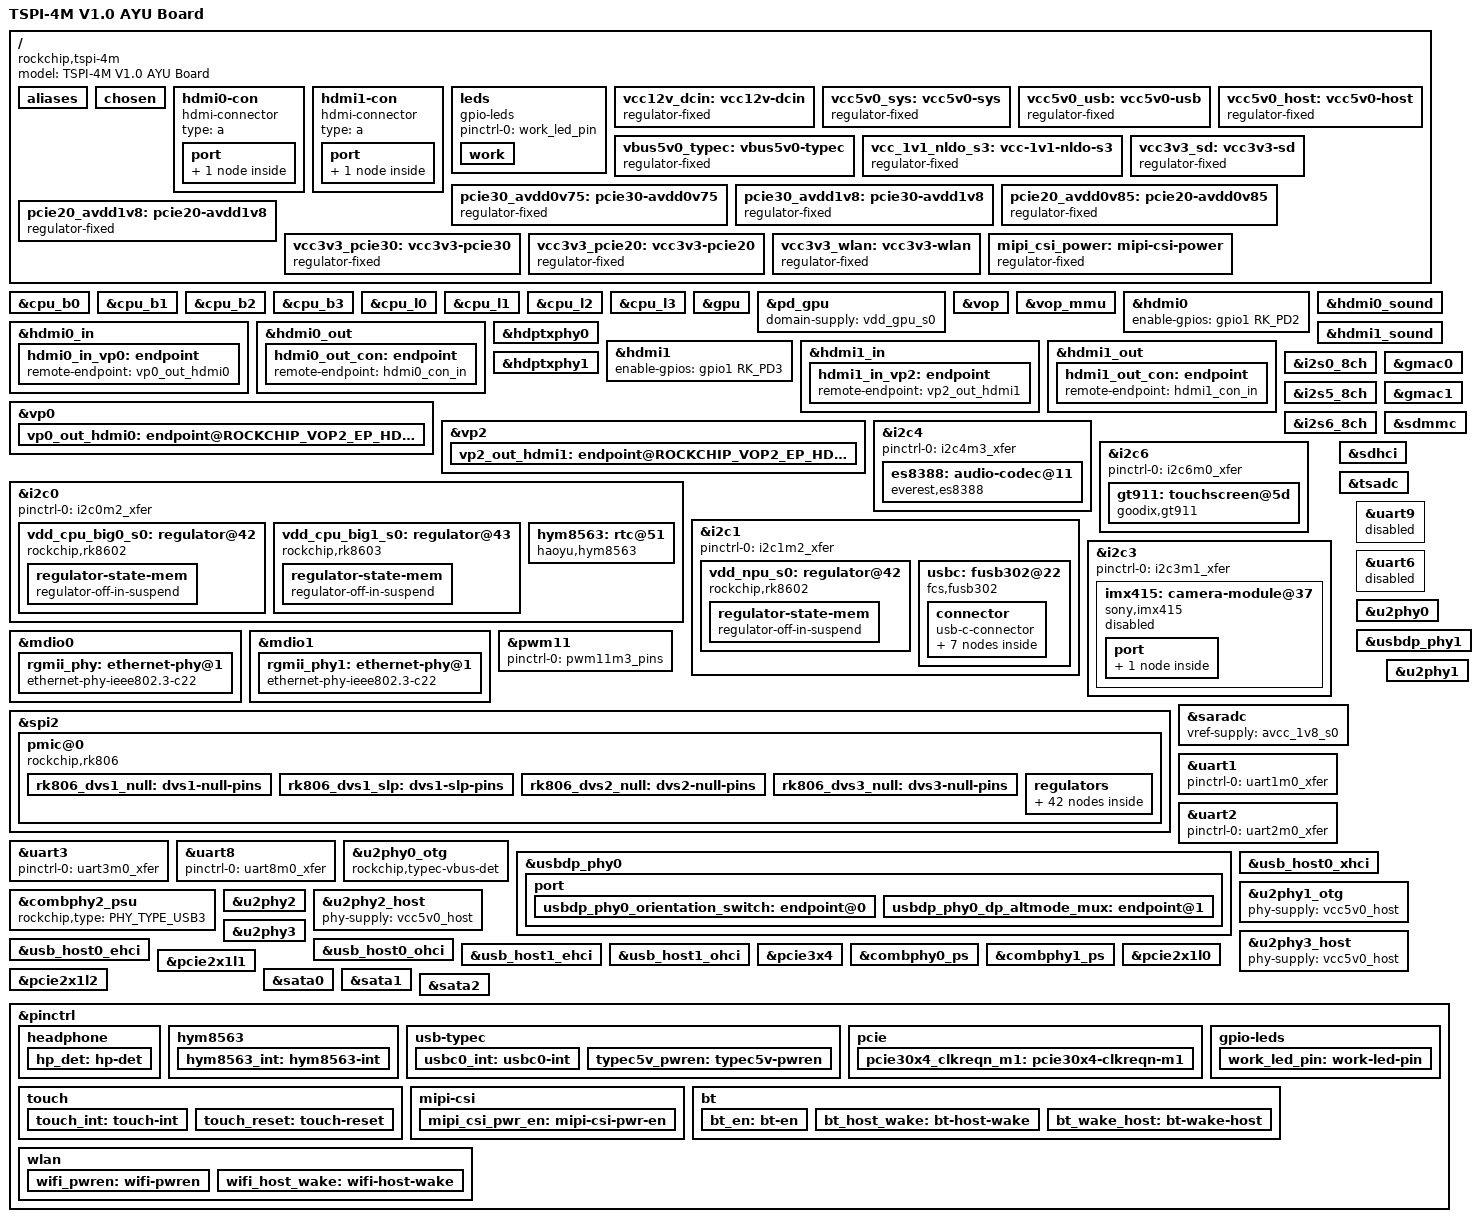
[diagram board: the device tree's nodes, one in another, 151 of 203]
// SPDX-License-Identifier: (GPL-2.0+ OR MIT)
/*
 * Rockchip RK3588 board: TSPI-4M V0.2 (ayu-tspi-4m)
 *
 * Mainline port of the vendor DTS at
 * arch/arm64/boot/dts/rockchip/tspi-4m-v0.2*.dts* (vendor kernel 6.1).
 *
 * Dropped from the vendor DTS, because mainline has no driver for it:
 *   - rockchip,multicodecs-card   (replaced by simple-audio-card)
 *   - rockchip_headset            (replaced by hp-det gpio + saradc)
 *   - rockchip,remotectl-pwm      (IR remote, pwm3)
 *   - csi2_dcphy0 / mipi0_csi2 / rkcif / rkcif_mipi_lvds / rkisp1_vir0
 *     (IMX415 sensor node is kept; the capture pipeline cannot be bound)
 *   - wlan-platdata / bluetooth-platdata  (probe nothing on mainline)
 *   - rk3588-android.dtsi
 *
 * TODO for the board owner (GPIOs are not in the backup diff):
 *   - WIFI_PWREN / WIFI_RST / WIFI_HOST_WAKE (pcie2x1l0 mini-pcie)
 *   - BT_EN / BT_RST / BT_HOST_WAKE / BT_WAKE_HOST (uart6)
 *   - RGMII PHY model on gmac0 (vendor: 千兆) and gmac1 PHY model
 *     (vendor: 千兆 via snps,reset-gpio gpio3 PB7)
 *   - eMMC capacity and DRAM type/speed for the rkbin ddrbin choice
 */

/dts-v1/;

#include <dt-bindings/gpio/gpio.h>
#include <dt-bindings/input/input.h>
#include <dt-bindings/interrupt-controller/irq.h>
#include <dt-bindings/pinctrl/rockchip.h>
#include <dt-bindings/power/rk3588-power.h>
#include <dt-bindings/soc/rockchip,vop2.h>
#include <dt-bindings/usb/pd.h>
#include "rk3588.dtsi"

/ {
	model = "TSPI-4M V1.0 AYU Board";
	compatible = "rockchip,tspi-4m", "rockchip,rk3588";

	aliases {
		/* mmc0 = SD card slot, mmc1 = eMMC.
		 * The serialN aliases come from rk3588s.dtsi (serialN = &uartN).
		 * u-boot resolves stdout-path through those aliases, so do not
		 * override them here. */
		mmc0 = &sdmmc;
		mmc1 = &sdhci;
	};

	chosen {
		/* uart2 m0 = serial@feb50000 = serial2. Resolved through the
		 * alias, so u-boot output does not depend on ttyS numbering.
		 * Keep serial2 in sync with the kernel DTS. */
		stdout-path = "serial2:1500000n8";

		/* ttyS numbering measured from the 6.18.59 boot log: the 8250
		 * driver probes DTB nodes in node order (uart0..uart9), so uart0
		 * (fd890000, disabled) takes index 0 and the debug port lands on
		 *   feb50000 uart2 -> ttyS2  (only wired console on this board)
		 *   feb60000 uart3 -> ttyS3   feb90000 uart6 -> ttyS6
		 *   febb0000 uart8 -> ttyS0   febc0000 uart9 -> ttyS1
		 * u-boot output resolves stdout-path through the alias and is
		 * unaffected. boot-rockchip64.cmd sets the same console anyway. */
		bootargs = "earlycon console=ttyS2,1500000";
	};

	hdmi0-con {
		compatible = "hdmi-connector";
		type = "a";

		port {
			hdmi0_con_in: endpoint {
				remote-endpoint = <&hdmi0_out_con>;
			};
		};
	};

	hdmi1-con {
		compatible = "hdmi-connector";
		type = "a";

		port {
			hdmi1_con_in: endpoint {
				remote-endpoint = <&hdmi1_out_con>;
			};
		};
	};

	/*
	 * Fan control is not needed by u-boot. The pwm11 fan and the
	 * thermal-zones block live only in the kernel device tree.
	 */

	leds {
		compatible = "gpio-leds";
		pinctrl-names = "default";
		pinctrl-0 = <&work_led_pin>;

		work {
			label = "tspi4m:white:work";
			gpios = <&gpio0 RK_PA0 GPIO_ACTIVE_HIGH>;
			linux,default-trigger = "heartbeat";
		};
	};

	/* ---- board regulators ---------------------------------------------- */

	vcc12v_dcin: vcc12v-dcin {
		compatible = "regulator-fixed";
		regulator-name = "vcc12v_dcin";
		regulator-always-on;
		regulator-boot-on;
		regulator-min-microvolt = <12000000>;
		regulator-max-microvolt = <12000000>;
	};

	vcc5v0_sys: vcc5v0-sys {
		compatible = "regulator-fixed";
		regulator-name = "vcc5v0_sys";
		regulator-always-on;
		regulator-boot-on;
		regulator-min-microvolt = <5000000>;
		regulator-max-microvolt = <5000000>;
		vin-supply = <&vcc12v_dcin>;
	};

	vcc5v0_usb: vcc5v0-usb {
		compatible = "regulator-fixed";
		regulator-name = "vcc5v0_usb";
		regulator-always-on;
		regulator-boot-on;
		regulator-min-microvolt = <5000000>;
		regulator-max-microvolt = <5000000>;
		enable-active-high;
		vin-supply = <&vcc12v_dcin>;
	};

	vcc5v0_host: vcc5v0-host {
		compatible = "regulator-fixed";
		regulator-name = "vcc5v0_host";
		regulator-boot-on;
		regulator-always-on;
		regulator-min-microvolt = <5000000>;
		regulator-max-microvolt = <5000000>;
		enable-active-high;
		vin-supply = <&vcc5v0_usb>;
		pinctrl-names = "default";
	};

	vbus5v0_typec: vbus5v0-typec {
		compatible = "regulator-fixed";
		regulator-name = "vbus5v0_typec";
		regulator-min-microvolt = <5000000>;
		regulator-max-microvolt = <5000000>;
		enable-active-high;
		gpio = <&gpio2 RK_PC3 GPIO_ACTIVE_HIGH>;
		vin-supply = <&vcc5v0_usb>;
		pinctrl-names = "default";
		pinctrl-0 = <&typec5v_pwren>;
	};

	vcc_1v1_nldo_s3: vcc-1v1-nldo-s3 {
		compatible = "regulator-fixed";
		regulator-name = "vcc_1v1_nldo_s3";
		regulator-always-on;
		regulator-boot-on;
		regulator-min-microvolt = <1100000>;
		regulator-max-microvolt = <1100000>;
		vin-supply = <&vcc5v0_sys>;
	};

	vcc3v3_sd: vcc3v3-sd {
		compatible = "regulator-fixed";
		regulator-name = "vcc3v3_sd";
		regulator-min-microvolt = <3300000>;
		regulator-max-microvolt = <3300000>;
		enable-active-high;
	};

	pcie30_avdd0v75: pcie30-avdd0v75 {
		compatible = "regulator-fixed";
		regulator-name = "pcie30_avdd0v75";
		regulator-boot-on;
		regulator-always-on;
		regulator-min-microvolt = <750000>;
		regulator-max-microvolt = <750000>;
		vin-supply = <&vdd_0v75_s0>;
	};

	pcie30_avdd1v8: pcie30-avdd1v8 {
		compatible = "regulator-fixed";
		regulator-name = "pcie30_avdd1v8";
		regulator-boot-on;
		regulator-always-on;
		regulator-min-microvolt = <1800000>;
		regulator-max-microvolt = <1800000>;
		vin-supply = <&avcc_1v8_s0>;
	};

	pcie20_avdd0v85: pcie20-avdd0v85 {
		compatible = "regulator-fixed";
		regulator-name = "pcie20_avdd0v85";
		regulator-always-on;
		regulator-boot-on;
		regulator-min-microvolt = <850000>;
		regulator-max-microvolt = <850000>;
		vin-supply = <&vdd_0v85_s0>;
	};

	pcie20_avdd1v8: pcie20-avdd1v8 {
		compatible = "regulator-fixed";
		regulator-name = "pcie20_avdd1v8";
		regulator-always-on;
		regulator-boot-on;
		regulator-min-microvolt = <1800000>;
		regulator-max-microvolt = <1800000>;
		vin-supply = <&avcc_1v8_s0>;
	};

	vcc3v3_pcie30: vcc3v3-pcie30 {
		compatible = "regulator-fixed";
		regulator-name = "vcc3v3_pcie30";
		regulator-min-microvolt = <3300000>;
		regulator-max-microvolt = <3300000>;
		enable-active-high;
		startup-delay-us = <5000>;
	};

	vcc3v3_pcie20: vcc3v3-pcie20 {
		compatible = "regulator-fixed";
		regulator-name = "vcc3v3_pcie20";
		regulator-min-microvolt = <3300000>;
		regulator-max-microvolt = <3300000>;
		enable-active-high;
		startup-delay-us = <5000>;
	};

	vcc3v3_wlan: vcc3v3-wlan {
		compatible = "regulator-fixed";
		regulator-name = "vcc3v3_wlan";
		regulator-min-microvolt = <3300000>;
		regulator-max-microvolt = <3300000>;
		enable-active-high;
		startup-delay-us = <5000>;
		vin-supply = <&vcc12v_dcin>;
		/*
		 * TODO: supply WIFI_PWREN here once the mini-pcie power pin is known.
		 * Without an enable gpio the 3V3 rail is treated as always on.
		 */
	};

	mipi_csi_power: mipi-csi-power {
		compatible = "regulator-fixed";
		regulator-name = "mipi_csi_power";
		regulator-min-microvolt = <3300000>;
		regulator-max-microvolt = <3300000>;
		regulator-always-on;
		regulator-boot-on;
		enable-active-high;
		gpio = <&gpio0 RK_PC5 GPIO_ACTIVE_HIGH>;
		pinctrl-names = "default";
		pinctrl-0 = <&mipi_csi_pwr_en>;
	};
};

/* ---- CPU / GPU / NPU supplies ---------------------------------------- */

&cpu_b0 {
	cpu-supply = <&vdd_cpu_big0_s0>;
	mem-supply = <&vdd_cpu_big0_s0>;
};

&cpu_b1 {
	cpu-supply = <&vdd_cpu_big0_s0>;
	mem-supply = <&vdd_cpu_big0_s0>;
};

&cpu_b2 {
	cpu-supply = <&vdd_cpu_big1_s0>;
	mem-supply = <&vdd_cpu_big1_s0>;
};

&cpu_b3 {
	cpu-supply = <&vdd_cpu_big1_s0>;
	mem-supply = <&vdd_cpu_big1_s0>;
};

&cpu_l0 {
	cpu-supply = <&vdd_cpu_lit_s0>;
	mem-supply = <&vdd_cpu_lit_mem_s0>;
};

&cpu_l1 {
	cpu-supply = <&vdd_cpu_lit_s0>;
	mem-supply = <&vdd_cpu_lit_mem_s0>;
};

&cpu_l2 {
	cpu-supply = <&vdd_cpu_lit_s0>;
	mem-supply = <&vdd_cpu_lit_mem_s0>;
};

&cpu_l3 {
	cpu-supply = <&vdd_cpu_lit_s0>;
	mem-supply = <&vdd_cpu_lit_mem_s0>;
};

&gpu {
	mali-supply = <&vdd_gpu_s0>;
	mem-supply = <&vdd_gpu_mem_s0>;
	status = "okay";
};

&pd_gpu {
	domain-supply = <&vdd_gpu_s0>;
};

/* NPU is not needed by u-boot, so the NPU regulator stays unused. */

/* ---- display --------------------------------------------------------- */

&vop {
	status = "okay";
};

&vop_mmu {
	status = "okay";
};

&hdmi0 {
	enable-gpios = <&gpio1 RK_PD2 GPIO_ACTIVE_HIGH>;
	status = "okay";
};

&hdmi0_in {
	hdmi0_in_vp0: endpoint {
		remote-endpoint = <&vp0_out_hdmi0>;
	};
};

&hdmi0_out {
	hdmi0_out_con: endpoint {
		remote-endpoint = <&hdmi0_con_in>;
	};
};

&hdmi0_sound {
	status = "okay";
};

&hdptxphy0 {
	status = "okay";
};

/* HDMI TX1 -> EDP1 cannot be enabled together */
&hdmi1 {
	enable-gpios = <&gpio1 RK_PD3 GPIO_ACTIVE_HIGH>;
	status = "okay";
};

&hdmi1_in {
	hdmi1_in_vp2: endpoint {
		remote-endpoint = <&vp2_out_hdmi1>;
	};
};

&hdmi1_out {
	hdmi1_out_con: endpoint {
		remote-endpoint = <&hdmi1_con_in>;
	};
};

&hdmi1_sound {
	status = "okay";
};

&hdptxphy1 {
	status = "okay";
};

&vp0 {
	vp0_out_hdmi0: endpoint@ROCKCHIP_VOP2_EP_HDMI0 {
		reg = <ROCKCHIP_VOP2_EP_HDMI0>;
		remote-endpoint = <&hdmi0_in_vp0>;
	};
};

&vp2 {
	vp2_out_hdmi1: endpoint@ROCKCHIP_VOP2_EP_HDMI1 {
		reg = <ROCKCHIP_VOP2_EP_HDMI1>;
		remote-endpoint = <&hdmi1_in_vp2>;
	};
};

/* ---- audio ----------------------------------------------------------- */
/* Vendor: es8388-sound (rockchip,multicodecs-card) + i2s0_8ch on i2c4.
 * Mainline: simple-audio-card, codec bound via everest,es8328 fallback.
 */
&i2s0_8ch {
	pinctrl-names = "default";
	pinctrl-0 = <&i2s0_lrck &i2s0_mclk &i2s0_sclk
		     &i2s0_sdi0 &i2s0_sdo0>;
	status = "okay";
};

/* HDMI sound uses i2s5_8ch / i2s6_8ch on mainline, not the board I2S. */
&i2s5_8ch {
	status = "okay";
};

&i2s6_8ch {
	status = "okay";
};

&i2c4 {
	pinctrl-names = "default";
	pinctrl-0 = <&i2c4m3_xfer>;
	status = "okay";

	es8388: audio-codec@11 {
		compatible = "everest,es8388", "everest,es8328";
		reg = <0x11>;
		clocks = <&cru I2S0_8CH_MCLKOUT>;
		assigned-clocks = <&cru I2S0_8CH_MCLKOUT>;
		assigned-clock-rates = <12288000>;
		AVDD-supply = <&vcc_3v3_s3>;
		DVDD-supply = <&vcc_1v8_s3>;
		HPVDD-supply = <&vcc_3v3_s3>;
		PVDD-supply = <&vcc_1v8_s3>;
		#sound-dai-cells = <0>;
	};
};

/* u-boot has no simple-audio-card driver; the analog_sound node is only
 * needed by the kernel DTS. Omitted here so dtc does not try to resolve
 * the &analog_sound phandle (u-boot rk3588 dtsi does not define it).
 */

/* ---- sensors / misc i2c --------------------------------------------- */

&i2c0 {
	pinctrl-names = "default";
	pinctrl-0 = <&i2c0m2_xfer>;
	status = "okay";

	vdd_cpu_big0_s0: regulator@42 {
		compatible = "rockchip,rk8602";
		reg = <0x42>;
		fcs,suspend-voltage-selector = <1>;
		regulator-name = "vdd_cpu_big0_s0";
		regulator-min-microvolt = <550000>;
		regulator-max-microvolt = <1050000>;
		regulator-ramp-delay = <2300>;
		vin-supply = <&vcc5v0_sys>;
		regulator-boot-on;
		regulator-always-on;

		regulator-state-mem {
			regulator-off-in-suspend;
		};
	};

	vdd_cpu_big1_s0: regulator@43 {
		compatible = "rockchip,rk8603", "rockchip,rk8602";
		reg = <0x43>;
		fcs,suspend-voltage-selector = <1>;
		regulator-name = "vdd_cpu_big1_s0";
		regulator-min-microvolt = <550000>;
		regulator-max-microvolt = <1050000>;
		regulator-ramp-delay = <2300>;
		vin-supply = <&vcc5v0_sys>;
		regulator-boot-on;
		regulator-always-on;

		regulator-state-mem {
			regulator-off-in-suspend;
		};
	};

	hym8563: rtc@51 {
		compatible = "haoyu,hym8563";
		reg = <0x51>;
		#clock-cells = <0>;
		clock-frequency = <32768>;
		clock-output-names = "hym8563";
		pinctrl-names = "default";
		pinctrl-0 = <&hym8563_int>;
		interrupt-parent = <&gpio0>;
		interrupts = <RK_PB0 IRQ_TYPE_LEVEL_LOW>;
		wakeup-source;
	};
};

&i2c1 {
	pinctrl-names = "default";
	pinctrl-0 = <&i2c1m2_xfer>;
	status = "okay";

	vdd_npu_s0: regulator@42 {
		compatible = "rockchip,rk8602";
		reg = <0x42>;
		fcs,suspend-voltage-selector = <1>;
		regulator-name = "vdd_npu_s0";
		regulator-min-microvolt = <550000>;
		regulator-max-microvolt = <950000>;
		regulator-ramp-delay = <2300>;
		vin-supply = <&vcc5v0_sys>;
		regulator-boot-on;
		regulator-always-on;

		regulator-state-mem {
			regulator-off-in-suspend;
		};
	};

	usbc: fusb302@22 {
		compatible = "fcs,fusb302";
		reg = <0x22>;
		interrupt-parent = <&gpio1>;
		interrupts = <RK_PC4 IRQ_TYPE_LEVEL_LOW>;
		pinctrl-names = "default";
		pinctrl-0 = <&usbc0_int>;
		vbus-supply = <&vbus5v0_typec>;
		status = "okay";

		connector {
			compatible = "usb-c-connector";
			label = "USB-C";
			data-role = "dual";
			power-role = "dual";
			try-power-role = "sink";
			op-sink-microwatt = <1000000>;
			sink-pdos = <PDO_FIXED(5000, 1000, PDO_FIXED_USB_COMM)>;
			source-pdos = <PDO_FIXED(5000, 3000, PDO_FIXED_USB_COMM)>;

			altmodes {
				#address-cells = <1>;
				#size-cells = <0>;

				altmode@0 {
					reg = <0>;
					svid = <0xff01>;
					vdo = <0xffffffff>;
				};
			};

			ports {
				#address-cells = <1>;
				#size-cells = <0>;

				port@0 {
					reg = <0>;
					usbc0_orien_sw: endpoint {
						remote-endpoint = <&usbdp_phy0_orientation_switch>;
					};
				};

				port@1 {
					reg = <1>;
					dp_altmode_mux: endpoint {
						remote-endpoint = <&usbdp_phy0_dp_altmode_mux>;
					};
				};
			};
		};
	};
};

&i2c6 {
	pinctrl-names = "default";
	pinctrl-0 = <&i2c6m0_xfer>;
	status = "okay";

	/* GT911 capacitive touchscreen */
	gt911: touchscreen@5d {
		compatible = "goodix,gt911";
		reg = <0x5d>;
		interrupt-parent = <&gpio1>;
		interrupts = <RK_PC5 IRQ_TYPE_EDGE_FALLING>;
		pinctrl-names = "default";
		pinctrl-0 = <&touch_int &touch_reset>;
		touchscreen-size-x = <1280>;
		touchscreen-size-y = <800>;
		/*
		 * TODO: confirm the touch reset GPIO and the active area /
		 * orientation. The vendor dtsi only named the device.
		 */
		G,Reset = <&gpio1 RK_PC6 GPIO_ACTIVE_LOW>;
		G,TouchSleep = "disabled";
		AVDD-supply = <&vcc_3v3_s0>;
		DOVDD-supply = <&vcc_3v3_s0>;
	};
};

&i2c3 {
	pinctrl-names = "default";
	pinctrl-0 = <&i2c3m1_xfer>;
	status = "okay";

	/*
	 * IMX415 8MP sensor. The sensor node stays so the module is probed
	 * and its clocks/IOs are described, but the capture pipeline
	 * (csi2_dcphy0 -> mipi0_csi2 -> rkcif -> rkcif_mipi_lvds ->
	 * rkcif_mipi_lvds_sditf -> rkisp1_vir0) has no mainline driver.
	 * Add it only when rkcif/mipi-csi2 land upstream.
	 */
	imx415: camera-module@37 {
		compatible = "sony,imx415";
		status = "disabled";
		reg = <0x37>;
		clocks = <&cru CLK_MIPI_CAMARAOUT_M1>;
		clock-names = "xvclk";
		pinctrl-names = "default", "sleep";
		pinctrl-0 = <&mipim0_camera1_clk>;
		power-domains = <&power RK3588_PD_VI>;
		rockchip,power-gpios = <&gpio0 RK_PC5 GPIO_ACTIVE_HIGH>;
		reset-gpios = <&gpio1 RK_PB5 GPIO_ACTIVE_LOW>;
		power-gpios = <&gpio1 RK_PB4 GPIO_ACTIVE_HIGH>;
		rockchip,camera-module-index = <2>;
		rockchip,camera-module-facing = "back";
		rockchip,camera-module-name = "CMK-OT2022-PX1";
		rockchip,camera-module-lens-name = "IR0147-50IRC-8M-F20";
		port {
			imx415_c1_out: endpoint {
				/*
				 * remote-endpoint omitted on purpose: there is
				 * no csi2_dcphy0 sink on mainline.
				 */
				data-lanes = <1 2 3 4>;
			};
		};
	};
};

/* ---- ethernet ------------------------------------------------------- */

&gmac0 {
	clock_in_out = "output";
	phy-handle = <&rgmii_phy>;
	phy-mode = "rgmii-rxid";
	pinctrl-0 = <&gmac0_miim &gmac0_tx_bus2 &gmac0_rx_bus2
		     &gmac0_rgmii_clk &gmac0_rgmii_bus>;
	pinctrl-names = "default";
	rx_delay = <0x00>;
	tx_delay = <0x43>;
	status = "okay";
};

&mdio0 {
	rgmii_phy: ethernet-phy@1 {
		compatible = "ethernet-phy-ieee802.3-c22";
		reg = <0x1>;
		reset-gpios = <&gpio2 RK_PC4 GPIO_ACTIVE_LOW>;
		/* TODO: confirm the gmac0 RGMII PHY part and its delays. */
	};
};

&gmac1 {
	clock_in_out = "output";
	phy-handle = <&rgmii_phy1>;
	phy-mode = "rgmii-rxid";
	pinctrl-0 = <&gmac1_miim &gmac1_tx_bus2 &gmac1_rx_bus2
		     &gmac1_rgmii_clk &gmac1_rgmii_bus>;
	pinctrl-names = "default";
	rx_delay = <0x00>;
	tx_delay = <0x43>;
	status = "okay";
};

&mdio1 {
	rgmii_phy1: ethernet-phy@1 {
		compatible = "ethernet-phy-ieee802.3-c22";
		reg = <0x1>;
		reset-gpios = <&gpio3 RK_PB7 GPIO_ACTIVE_LOW>;
		/* Vendor: snps,reset-gpio = gpio3 RK_PB7. PHY part unknown. */
	};
};

/* ---- CAN ----------------------------------------------------------- */
/*
 * CAN is not needed by u-boot. U-Boot has no drivers/net/can and the rk3588
 * CAN nodes are not in the dts/upstream sync of this branch (Armbian adds
 * them for v2026.04). &can0 / &can1 would not resolve, so they live only in
 * the kernel device tree.
 */

/* ---- pwm ----------------------------------------------------------- */
&pwm11 {
	pinctrl-names = "default";
	pinctrl-0 = <&pwm11m3_pins>;
	status = "okay";
};

/* pwm3: vendor used rockchip,remotectl-pwm for the IR remote. No mainline
 * driver. Left disabled; see the NPU/CSI gaps in the board README. */

/* ---- storage ------------------------------------------------------- */

&sdmmc {
	status = "okay";
	bus-width = <4>;
	cap-sd-highspeed;
	sd-uhs-sdr104;
	max-frequency = <200000000>;
	disable-wp;
	vmmc-supply = <&vcc3v3_sd>;
	vqmmc-supply = <&vccio_sd_s0>;
};

&sdhci {
	status = "okay";
	bus-width = <8>;
	no-sdio;
	no-sd;
	non-removable;
	max-frequency = <200000000>;
	mmc-hs400-1_8v;
	mmc-hs400-enhanced-strobe;
};

/* ---- PMIC ---------------------------------------------------------- */

&spi2 {
	assigned-clocks = <&cru CLK_SPI2>;
	assigned-clock-rates = <200000000>;
	num-cs = <1>;
	pinctrl-names = "default";
	pinctrl-0 = <&spi2m2_cs0 &spi2m2_pins>;
	status = "okay";

	pmic@0 {
		compatible = "rockchip,rk806";
		reg = <0x0>;
		interrupt-parent = <&gpio0>;
		interrupts = <7 IRQ_TYPE_LEVEL_LOW>;
		pinctrl-names = "default", "pmic-power-off";
		pinctrl-0 = <&pmic_pins>, <&rk806_dvs1_null>,
			    <&rk806_dvs2_null>, <&rk806_dvs3_null>;
		pinctrl-1 = <&rk806_dvs1_slp>, <&rk806_dvs2_null>,
			    <&rk806_dvs3_null>;

		spi-max-frequency = <1000000>;
		system-power-controller;

		vcc1-supply = <&vcc5v0_sys>;
		vcc2-supply = <&vcc5v0_sys>;
		vcc3-supply = <&vcc5v0_sys>;
		vcc4-supply = <&vcc5v0_sys>;
		vcc5-supply = <&vcc5v0_sys>;
		vcc6-supply = <&vcc5v0_sys>;
		vcc7-supply = <&vcc5v0_sys>;
		vcc8-supply = <&vcc5v0_sys>;
		vcc9-supply = <&vcc5v0_sys>;
		vcc10-supply = <&vcc5v0_sys>;
		vcc11-supply = <&vcc_2v0_pldo_s3>;
		vcc12-supply = <&vcc5v0_sys>;
		vcc13-supply = <&vcc_1v1_nldo_s3>;
		vcc14-supply = <&vcc_1v1_nldo_s3>;
		vcca-supply = <&vcc5v0_sys>;

		gpio-controller;
		#gpio-cells = <2>;

		rk806_dvs1_null: dvs1-null-pins {
			pins = "gpio_pwrctrl1";
			function = "pin_fun0";
		};

		rk806_dvs1_slp: dvs1-slp-pins {
			pins = "gpio_pwrctrl1";
			function = "pin_fun1";
		};

		rk806_dvs2_null: dvs2-null-pins {
			pins = "gpio_pwrctrl2";
			function = "pin_fun0";
		};

		rk806_dvs3_null: dvs3-null-pins {
			pins = "gpio_pwrctrl3";
			function = "pin_fun0";
		};

		regulators {
			vdd_gpu_s0: vdd_gpu_mem_s0: dcdc-reg1 {
				regulator-boot-on;
				regulator-enable-ramp-delay = <400>;
				regulator-min-microvolt = <550000>;
				regulator-max-microvolt = <950000>;
				regulator-name = "vdd_gpu_s0";
				regulator-ramp-delay = <12500>;

				regulator-state-mem {
					regulator-off-in-suspend;
				};
			};

			vdd_cpu_lit_s0: vdd_cpu_lit_mem_s0: dcdc-reg2 {
				regulator-always-on;
				regulator-boot-on;
				regulator-min-microvolt = <550000>;
				regulator-max-microvolt = <950000>;
				regulator-name = "vdd_cpu_lit_s0";
				regulator-ramp-delay = <12500>;

				regulator-state-mem {
					regulator-off-in-suspend;
				};
			};

			vdd_log_s0: dcdc-reg3 {
				regulator-always-on;
				regulator-boot-on;
				regulator-min-microvolt = <675000>;
				regulator-max-microvolt = <800000>;
				regulator-name = "vdd_log_s0";
				regulator-ramp-delay = <12500>;

				regulator-state-mem {
					regulator-off-in-suspend;
					regulator-suspend-microvolt = <750000>;
				};
			};

			vdd_vdenc_s0: vdd_vdenc_mem_s0: dcdc-reg4 {
				regulator-always-on;
				regulator-boot-on;
				regulator-min-microvolt = <550000>;
				regulator-max-microvolt = <950000>;
				regulator-name = "vdd_vdenc_s0";
				regulator-ramp-delay = <12500>;

				regulator-state-mem {
					regulator-off-in-suspend;
				};
			};

			vdd_ddr_s0: dcdc-reg5 {
				regulator-always-on;
				regulator-boot-on;
				regulator-min-microvolt = <675000>;
				regulator-max-microvolt = <900000>;
				regulator-name = "vdd_ddr_s0";
				regulator-ramp-delay = <12500>;

				regulator-state-mem {
					regulator-off-in-suspend;
					regulator-suspend-microvolt = <850000>;
				};
			};

			vdd2_ddr_s3: dcdc-reg6 {
				regulator-always-on;
				regulator-boot-on;
				regulator-name = "vdd2_ddr_s3";

				regulator-state-mem {
					regulator-on-in-suspend;
				};
			};

			vcc_2v0_pldo_s3: dcdc-reg7 {
				regulator-always-on;
				regulator-boot-on;
				regulator-min-microvolt = <2000000>;
				regulator-max-microvolt = <2000000>;
				regulator-name = "vdd_2v0_pldo_s3";
				regulator-ramp-delay = <12500>;

				regulator-state-mem {
					regulator-on-in-suspend;
					regulator-suspend-microvolt = <2000000>;
				};
			};

			vcc_3v3_s3: dcdc-reg8 {
				regulator-always-on;
				regulator-boot-on;
				regulator-min-microvolt = <3300000>;
				regulator-max-microvolt = <3300000>;
				regulator-name = "vcc_3v3_s3";

				regulator-state-mem {
					regulator-on-in-suspend;
					regulator-suspend-microvolt = <3300000>;
				};
			};

			vddq_ddr_s0: dcdc-reg9 {
				regulator-always-on;
				regulator-boot-on;
				regulator-name = "vddq_ddr_s0";

				regulator-state-mem {
					regulator-off-in-suspend;
				};
			};

			vcc_1v8_s3: dcdc-reg10 {
				regulator-always-on;
				regulator-boot-on;
				regulator-min-microvolt = <1800000>;
				regulator-max-microvolt = <1800000>;
				regulator-name = "vcc_1v8_s3";

				regulator-state-mem {
					regulator-on-in-suspend;
					regulator-suspend-microvolt = <1800000>;
				};
			};

			avcc_1v8_s0: pldo-reg1 {
				regulator-always-on;
				regulator-boot-on;
				regulator-min-microvolt = <1800000>;
				regulator-max-microvolt = <1800000>;
				regulator-name = "avcc_1v8_s0";

				regulator-state-mem {
					regulator-off-in-suspend;
				};
			};

			vcc_1v8_s0: pldo-reg2 {
				regulator-always-on;
				regulator-boot-on;
				regulator-min-microvolt = <1800000>;
				regulator-max-microvolt = <1800000>;
				regulator-name = "vcc_1v8_s0";

				regulator-state-mem {
					regulator-off-in-suspend;
					regulator-suspend-microvolt = <1800000>;
				};
			};

			avdd_1v2_s0: pldo-reg3 {
				regulator-always-on;
				regulator-boot-on;
				regulator-min-microvolt = <1200000>;
				regulator-max-microvolt = <1200000>;
				regulator-name = "avdd_1v2_s0";

				regulator-state-mem {
					regulator-off-in-suspend;
				};
			};

			vcc_3v3_s0: pldo-reg4 {
				regulator-always-on;
				regulator-boot-on;
				regulator-min-microvolt = <3300000>;
				regulator-max-microvolt = <3300000>;
				regulator-ramp-delay = <12500>;
				regulator-name = "vcc_3v3_s0";

				regulator-state-mem {
					regulator-off-in-suspend;
				};
			};

			vccio_sd_s0: pldo-reg5 {
				regulator-always-on;
				regulator-boot-on;
				regulator-min-microvolt = <1800000>;
				regulator-max-microvolt = <3300000>;
				regulator-ramp-delay = <12500>;
				regulator-name = "vccio_sd_s0";

				regulator-state-mem {
					regulator-off-in-suspend;
				};
			};

			pldo6_s3: pldo-reg6 {
				regulator-always-on;
				regulator-boot-on;
				regulator-min-microvolt = <1800000>;
				regulator-max-microvolt = <1800000>;
				regulator-name = "pldo6_s3";

				regulator-state-mem {
					regulator-on-in-suspend;
					regulator-suspend-microvolt = <1800000>;
				};
			};

			vdd_0v75_s3: nldo-reg1 {
				regulator-always-on;
				regulator-boot-on;
				regulator-min-microvolt = <750000>;
				regulator-max-microvolt = <750000>;
				regulator-name = "vdd_0v75_s3";

				regulator-state-mem {
					regulator-on-in-suspend;
					regulator-suspend-microvolt = <750000>;
				};
			};

			vdd_ddr_pll_s0: nldo-reg2 {
				regulator-always-on;
				regulator-boot-on;
				regulator-min-microvolt = <850000>;
				regulator-max-microvolt = <850000>;
				regulator-name = "vdd_ddr_pll_s0";

				regulator-state-mem {
					regulator-off-in-suspend;
					regulator-suspend-microvolt = <850000>;
				};
			};

			avdd_0v75_s0: nldo-reg3 {
				regulator-always-on;
				regulator-boot-on;
				regulator-min-microvolt = <750000>;
				regulator-max-microvolt = <750000>;
				regulator-name = "avdd_0v75_s0";

				regulator-state-mem {
					regulator-off-in-suspend;
				};
			};

			vdd_0v85_s0: nldo-reg4 {
				regulator-always-on;
				regulator-boot-on;
				regulator-min-microvolt = <850000>;
				regulator-max-microvolt = <850000>;
				regulator-name = "vdd_0v85_s0";

				regulator-state-mem {
					regulator-off-in-suspend;
				};
			};

			vdd_0v75_s0: nldo-reg5 {
				regulator-always-on;
				regulator-boot-on;
				regulator-min-microvolt = <750000>;
				regulator-max-microvolt = <750000>;
				regulator-name = "vdd_0v75_s0";

				regulator-state-mem {
					regulator-off-in-suspend;
				};
			};
		};
	};
};

/* ---- temperature / adc --------------------------------------------- */

&tsadc {
	status = "okay";
};

&saradc {
	vref-supply = <&avcc_1v8_s0>;
	status = "okay";
};

/* ---- serial -------------------------------------------------------- */

&uart1 {
	status = "okay";
	pinctrl-names = "default";
	pinctrl-0 = <&uart1m0_xfer>;
};

&uart2 {
	status = "okay";
	pinctrl-names = "default";
	pinctrl-0 = <&uart2m0_xfer>;
};

&uart3 {
	status = "okay";
	pinctrl-names = "default";
	pinctrl-0 = <&uart3m0_xfer>;
};

&uart8 {
	status = "okay";
	pinctrl-names = "default";
	pinctrl-0 = <&uart8m0_xfer>;
};

&uart9 {
	/* No wired peer. uart9m0_xfer (gpio2 PC4/PC2) clashes with
	 * gmac0_rx_bus2 on gpio2-18 (PC2). Keep disabled, like the vendor.
	 */
	status = "disabled";
};

&uart6 {
	/* No wired peer: WiFi is PCIe, BT is USB. Keep disabled. */
	status = "disabled";
};

/* ---- usb ----------------------------------------------------------- */

&u2phy0 {
	status = "okay";
};

&u2phy0_otg {
	status = "okay";
	rockchip,typec-vbus-det;
};

&usbdp_phy0 {
	orientation-switch;
	svid = <0xff01>;
	sbu1-dc-gpios = <&gpio4 RK_PA0 GPIO_ACTIVE_HIGH>;
	sbu2-dc-gpios = <&gpio4 RK_PA1 GPIO_ACTIVE_HIGH>;

	port {
		#address-cells = <1>;
		#size-cells = <0>;

		usbdp_phy0_orientation_switch: endpoint@0 {
			reg = <0>;
			remote-endpoint = <&usbc0_orien_sw>;
		};

		usbdp_phy0_dp_altmode_mux: endpoint@1 {
			reg = <1>;
			remote-endpoint = <&dp_altmode_mux>;
		};
	};
};

&usbdp_phy1 {
	status = "okay";
};

/* u-boot has no dwc3 OTG role-switch driver; the kernel-side
 * usbdrd_dwc3_0 node is omitted. USB mass storage for ums uses
 * usb_host0_xhci with dr_mode="peripheral", already enabled below.
 */

&usb_host0_xhci {
	dr_mode = "peripheral";
	maximum-speed = "high-speed";
	status = "okay";
};

&u2phy1 {
	status = "okay";
};

&u2phy1_otg {
	phy-supply = <&vcc5v0_host>;
	status = "okay";
};

&combphy2_psu {
	status = "okay";
	rockchip,type = <PHY_TYPE_USB3>;
};

&u2phy2 {
	status = "okay";
};

&u2phy2_host {
	phy-supply = <&vcc5v0_host>;
	status = "okay";
};

&u2phy3 {
	status = "okay";
};

&u2phy3_host {
	phy-supply = <&vcc5v0_host>;
	status = "okay";
};

&usb_host0_ehci {
	status = "okay";
};

&usb_host0_ohci {
	status = "okay";
};

&usb_host1_ehci {
	status = "okay";
};

&usb_host1_ohci {
	status = "okay";
};

/* ---- pcie / sata --------------------------------------------------- */

/* u-boot has no pcie30phy driver, and PHY_MODE_PCIE_AGGREGATION is a
 * kernel-only macro (include/dt-bindings/phy/phy-snps-pcie3.h, absent in
 * u-boot). Omit the node; the kernel DTS carries it.
 */

&pcie3x4 {
	reset-gpios = <&gpio0 RK_PD0 GPIO_ACTIVE_HIGH>;
	vpcie3v3-supply = <&vcc3v3_pcie30>;
	pinctrl-names = "default";
	pinctrl-0 = <&pcie30x4_clkreqn_m1>;
	status = "okay";
	num-lanes = <4>;
	max-link-width = <4>;
	max-link-speed = <3>;
};

&combphy0_ps {
	status = "okay";
};

&combphy1_ps {
	status = "okay";
};

&pcie2x1l0 {
	reset-gpios = <&gpio4 RK_PA5 GPIO_ACTIVE_HIGH>;
	disable-gpios = <&gpio0 RK_PC4 GPIO_ACTIVE_HIGH>;
	vpcie3v3-supply = <&vcc3v3_pcie20>;
	status = "okay";
};

&pcie2x1l1 {
	reset-gpios = <&gpio4 RK_PB6 GPIO_ACTIVE_HIGH>;
	vpcie3v3-supply = <&vcc3v3_pcie20>;
	status = "okay";
};

&pcie2x1l2 {
	reset-gpios = <&gpio3 RK_PD1 GPIO_ACTIVE_LOW>;
	disable-gpios = <&gpio3 RK_PC1 GPIO_ACTIVE_HIGH>;
	vpcie3v3-supply = <&vcc3v3_pcie20>;
	status = "okay";
};

&sata0 {
	status = "okay";
};

&sata1 {
	status = "okay";
};

&sata2 {
	status = "okay";
};

/* ---- pinctrl ------------------------------------------------------- */

&pinctrl {
	headphone {
		hp_det: hp-det {
			rockchip,pins =
				/* hp detect */
				<0 RK_PB2 RK_FUNC_GPIO &pcfg_pull_none>,
				/* external amp enable, shared with CAN1 */
				<4 RK_PB2 RK_FUNC_GPIO &pcfg_pull_down>,
				/* earphone ctl */
				<1 RK_PD5 RK_FUNC_GPIO &pcfg_pull_down>;
		};
	};

	hym8563 {
		hym8563_int: hym8563-int {
			rockchip,pins = <0 RK_PB0 RK_FUNC_GPIO &pcfg_pull_up>;
		};
	};

	usb-typec {
		usbc0_int: usbc0-int {
			rockchip,pins = <1 RK_PC4 RK_FUNC_GPIO &pcfg_pull_up>;
		};

		typec5v_pwren: typec5v-pwren {
			rockchip,pins = <2 RK_PC3 RK_FUNC_GPIO &pcfg_pull_none>;
		};
	};

	pcie {
		pcie30x4_clkreqn_m1: pcie30x4-clkreqn-m1 {
			rockchip,pins = <0 RK_PC6 RK_FUNC_GPIO &pcfg_output_low>;
		};
	};

	touch {
		touch_int: touch-int {
			rockchip,pins = <1 RK_PC5 RK_FUNC_GPIO &pcfg_pull_up>;
		};

		touch_reset: touch-reset {
			rockchip,pins = <1 RK_PC6 RK_FUNC_GPIO &pcfg_pull_none>;
		};
	};

	mipi-csi {
		mipi_csi_pwr_en: mipi-csi-pwr-en {
			rockchip,pins = <0 RK_PC5 RK_FUNC_GPIO &pcfg_pull_none>;
		};
	};

	gpio-leds {
		work_led_pin: work-led-pin {
			rockchip,pins = <0 RK_PA0 RK_FUNC_GPIO &pcfg_pull_none>;
		};
	};

	bt {
		bt_en: bt-en {
			rockchip,pins = <1 RK_PA1 RK_FUNC_GPIO &pcfg_pull_none>;
		};

		bt_host_wake: bt-host-wake {
			rockchip,pins = <1 RK_PA0 RK_FUNC_GPIO &pcfg_pull_down>;
		};

		bt_wake_host: bt-wake-host {
			rockchip,pins = <1 RK_PA2 RK_FUNC_GPIO &pcfg_pull_down>;
		};
	};

	wlan {
		wifi_pwren: wifi-pwren {
			rockchip,pins = <1 RK_PB0 RK_FUNC_GPIO &pcfg_pull_none>;
		};

		wifi_host_wake: wifi-host-wake {
			rockchip,pins = <1 RK_PA7 RK_FUNC_GPIO &pcfg_pull_down>;
		};
	};
};
